# STM32H5F5 register map
File version: 1.0
CPU: CM33 r0p0, little endian, MPU, FPU, 4 interrupt priority bits
Registers are 32-bit, read-write, reset 0x0 unless marked. A register's access mark holds for its fields unless they carry their own. Offsets are from the block's base; [hi:lo] are bit positions; {n}, {i} and the like mark numbered series; 'fields as' and 'values as' point back to an identical list.

## RCC (part 1 of 2) — RCC register block
Base 0x44020C00
Same registers: RCC_S 0x54020C00
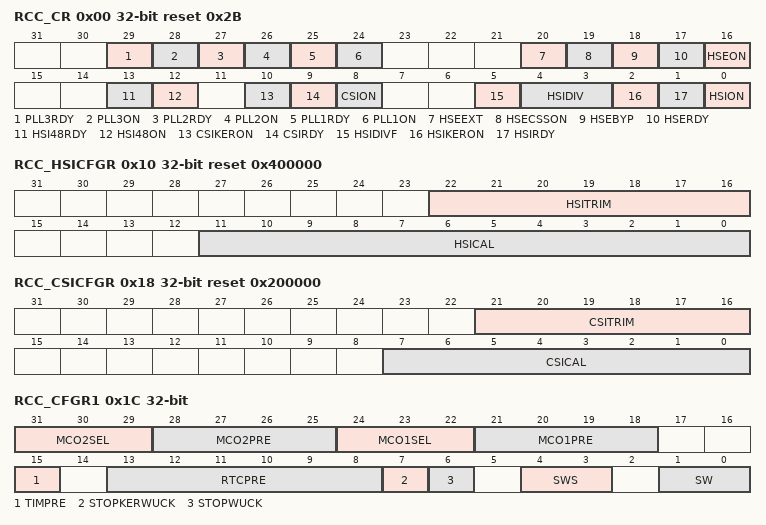
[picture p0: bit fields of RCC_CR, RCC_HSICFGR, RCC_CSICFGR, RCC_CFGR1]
0x00 RCC_CR reset 0x2B — RCC clock control register
  [29] PLL3RDY ro — PLL3 clock ready flag
    0=PLL3 unlocked (default after reset); 1=PLL3 locked
  [28] PLL3ON — PLL3 enable
    0=PLL3 OFF (default after reset); 1=PLL3 ON
  [27] PLL2RDY ro — PLL2 clock ready flag
    0=PLL2 unlocked; 1=PLL2 locked
  [26] PLL2ON — PLL2 enable
    0=PLL2 OFF (default after reset); 1=PLL2 ON
  [25] PLL1RDY ro — PLL1 clock ready flag
    0=PLL1 unlocked (default after reset); 1=PLL1 locked
  [24] PLL1ON — PLL1 enable
    0=PLL1 OFF (default after reset); 1=PLL1 ON
  [20] HSEEXT — external high speed clock type in Bypass mode
    0=HSE in analog mode (default after reset); 1=HSE in digital mode
  [19] HSECSSON — HSE clock security system enable
    0=CSS on HSE OFF (clock detector OFF) (default after reset); 1=CSS on HSE ON (clock detector ON if the HSE oscillator is stable, OFF if not)
  [18] HSEBYP — HSE clock bypass
    0=HSE oscillator not bypassed (default after reset); 1=HSE oscillator bypassed with an external clock
  [17] HSERDY ro — HSE clock ready flag
    0=HSE clock is not ready (default after reset); 1=HSE clock is ready
  [16] HSEON — HSE clock enable
    0=HSE is OFF (default after reset); 1=HSE is ON
  [13] HSI48RDY ro — HSI48 clock ready flag
    0=HSI48 clock is not ready (default after reset); 1=HSI48 clock is ready
  [12] HSI48ON — HSI48 clock enable
    0=HSI48 is OFF (default after reset); 1=HSI48 is ON
  [10] CSIKERON — CSI clock enable in Stop mode
    0=no effect on CSI (default after reset); 1=CSI is forced to ON even in Stop mode
  [9] CSIRDY ro — CSI clock ready flag
    0=CSI clock is not ready (default after reset); 1=CSI clock is ready
  [8] CSION — CSI clock enable
    0=CSI is OFF (default after reset); 1=CSI is ON
  [5] HSIDIVF ro — HSI divider flag
    0=new division ratio not yet propagated to hsi_ck, hsi_ker_ck (default after reset); 1=hsi_ck, hsi_ker_ck clock frequency reflects the new HSIDIV value (default register value when the clock setting is completed)
  [4:3] HSIDIV — HSI clock divider
    0=division by 1, hsi_ck, hsi_ker_ck = 64 MHz; 1=division by 2, hsi_ck, hsi_ker_ck = 32 MHz (default after reset); 2=division by 4, hsi_ck, hsi_ker_ck = 16 MHz; 3=division by 8, hsi_ck, hsi_ker_ck = 8 MHz
  [2] HSIKERON — HSI clock enable in Stop mode
    0=no effect on HSI (default after reset); 1=HSI is forced to ON even in Stop mode
  [1] HSIRDY ro — HSI clock ready flag
    0=HSI clock is not ready (default after reset); 1=HSI clock is ready
  [0] HSION — HSI clock enable
    0=HSI is OFF; 1=HSI is ON (default after reset)
0x10 RCC_HSICFGR reset 0x400000 (reset mask 0xFFFFF000) — RCC HSI calibration register
  [22:16] HSITRIM — HSI clock trimming
  [11:0] HSICAL ro — HSI clock calibration
0x14 RCC_CRRCR ro (reset mask 0xFFFFF000) — RCC clock recovery RC register
  [9:0] HSI48CAL — Internal RC 48 MHz clock calibration
0x18 RCC_CSICFGR reset 0x200000 (reset mask 0xFFFFF000) — RCC CSI calibration register
  [21:16] CSITRIM — CSI clock trimming
  [7:0] CSICAL — CSI clock calibration
0x1C RCC_CFGR1 — RCC clock configuration register1
  [31:29] MCO2SEL — microcontroller clock output 2
    0=system clock selected (sys_ck) (default after reset); 1=PLL2 oscillator clock selected (pll2_p_ck); 2=HSE clock selected (hse_ck); 3=PLL1 clock selected (pll1_p_ck); 4=CSI clock selected (csi_ck); 5=LSI clock selected (lsi_ck)
  [28:25] MCO2PRE — MCO2 prescaler
    0=prescaler disabled (default after reset); 1=division by 1 (bypass); 2=division by 2; 3=division by 3; 4=division by 4; 15=division by 15
  [24:22] MCO1SEL — Microcontroller clock output 1
    0=HSI clock selected (hsi_ck) (default after reset); 1=LSE oscillator clock selected (lse_ck); 2=HSE clock selected (hse_ck); 3=PLL1 clock selected (pll1_q_ck); 4=HSI48 clock selected (hsi48_ck)
  [21:18] MCO1PRE — MCO1 prescaler
    values as MCO2PRE
  [15] TIMPRE — timers clocks prescaler selection
    0=The timers kernel clock is equal to rcc_hclk1 if PPRE1 or PPRE2 corresponds to a division by 1 or 2, else it is equal to 2 x Fless thansub>rcc_pclk1less than/sub> or 2 x Fless thansub>rcc_pclk2less than/sub> (default after reset); 1=The timers kernel clock is equal to 2 x Fless thansub>rcc_pclk1less than/sub> or 2 x Fless thansub>rcc_pclk2less than/sub> if PPRE1 or PPRE2 corresponds to a division by 1, 2, or 4, else it is equal to 4 x Fless thansub>rcc_pclk1less than/sub> or 4 x Fless thansub>rcc_pclk2less than/sub>
  [13:8] RTCPRE — HSE division factor for RTC clock
    0=no clock (default after reset); 1=no clock; 2=HSE/2; 3=HSE/3; 4=HSE/4; 62=HSE/62; 63=HSE/63
  [7] STOPKERWUCK — kernel clock selection after a wake-up from system Stop
    0=HSI selected as wake-up clock from system Stop (default after reset); 1=CSI selected as wake-up clock from system Stop
  [6] STOPWUCK — system clock selection after a wake-up from system Stop
    1=CSI selected as wake-up clock from system Stop
  [4:3] SWS ro — system clock switch status
    0=HSI used as system clock (hsi_ck) (default after reset); 1=CSI used as system clock (csi_ck); 2=HSE used as system clock (hse_ck); 3=PLL1 used as system clock (pll1_p_ck)
  [1:0] SW — system clock and trace clock switch
    0=HSI selected as system clock (hsi_ck) (default after reset); 1=CSI selected as system clock (csi_ck); 2=HSE selected as system clock (hse_ck); 3=PLL1 selected as system clock (pll1_p_ck for sys_ck)
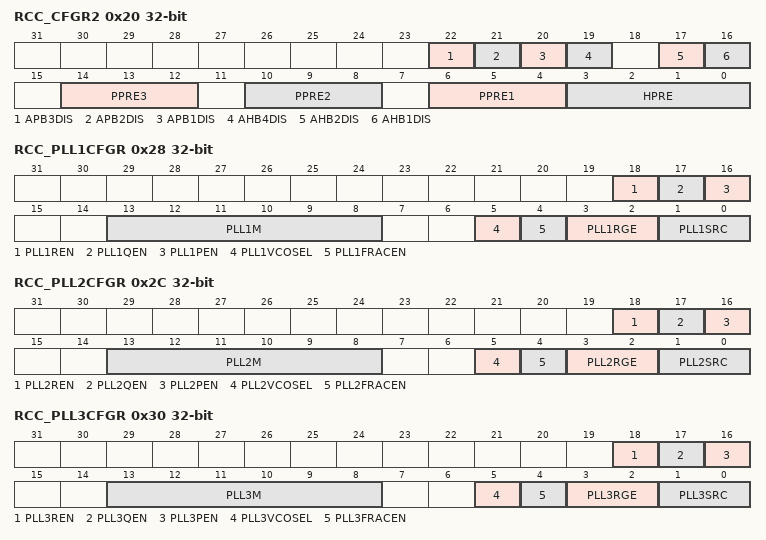
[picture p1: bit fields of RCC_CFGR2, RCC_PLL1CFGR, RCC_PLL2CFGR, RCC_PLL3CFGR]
0x20 RCC_CFGR2 — RCC CPU domain clock configuration register 2
  [22] APB3DIS — APB3 clock disable value.
    0=APB3 clock enabled, distributed to peripherals according to their dedicated clock enable control bits; 1=APB3 clock disabled
  [21] APB2DIS — APB2 clock disable value
    0=APB2 clock enabled, distributed to peripherals according to their dedicated clock enable control bits; 1=APB2 clock disabled
  [20] APB1DIS — APB1 clock disable value
    0=APB1 clock enabled, distributed to peripherals according to their dedicated clock enable control bits; 1=APB1 clock disabled
  [19] AHB4DIS — AHB4 clock disable
    0=AHB4 clock enabled, distributed to peripherals according to their dedicated clock enable control bits; 1=AHB4 clock disabled
  [17] AHB2DIS — AHB2 clock disable
    0=AHB2 clock enabled, distributed to peripherals according to their dedicated clock enable control bits; 1=AHB2 clock disabled
  [16] AHB1DIS — AHB1 clock disable
    0=AHB1 clock enabled, distributed to peripherals according to their dedicated clock enable control bits; 1=AHB1 clock disabled
  [14:12] PPRE3 — APB low-speed prescaler (APB3)
    4=rcc_pclk3 = rcc_hclk1 / 2; 5=rcc_pclk3 = rcc_hclk1 / 4; 6=rcc_pclk3 = rcc_hclk1 / 8; 7=rcc_pclk3 = rcc_hclk1 / 16
  [10:8] PPRE2 — APB high-speed prescaler (APB2)
    4=rcc_pclk2 = rcc_hclk1 / 2; 5=rcc_pclk2 = rcc_hclk1 / 4; 6=rcc_pclk2 = rcc_hclk1 / 8; 7=rcc_pclk2 = rcc_hclk1 / 16
  [6:4] PPRE1 — APB low-speed prescaler (APB1)
    4=rcc_pclk1 = rcc_hclk1 / 2; 5=rcc_pclk1 = rcc_hclk1 / 4; 6=rcc_pclk1 = rcc_hclk1 / 8; 7=rcc_pclk1 = rcc_hclk1 / 16
  [3:0] HPRE — AHB prescaler
    8=rcc_hclk = sys_ck / 2; 9=rcc_hclk = sys_ck / 4; 10=rcc_hclk = sys_ck / 8; 11=rcc_hclk = sys_ck / 16; 12=rcc_hclk = sys_ck / 64; 13=rcc_hclk = sys_ck / 128; 14=rcc_hclk = sys_ck / 256; 15=rcc_hclk = sys_ck / 512
0x28 RCC_PLL1CFGR — RCC PLL clock source selection register
  [18] PLL1REN — PLL1 DIVR divider output enable
    0=pll1_r_ck output disabled (default after reset); 1=pll1_r_ck output enabled
  [17] PLL1QEN — PLL1 DIVQ divider output enable
    0=pll1_q_ck output disabled (default after reset); 1=pll1_q_ck output enabled
  [16] PLL1PEN — PLL1 DIVP divider output enable
    0=pll1_p_ck output disabled (default after reset); 1=pll1_p_ck output enabled
  [13:8] PLL1M — prescaler for PLL1
    0=prescaler disabled (default after reset); 1=division by 1 (bypass); 2=division by 2; 3=division by 3; 32=division by 32; 63=division by 63
  [5] PLL1VCOSEL — PLL1 VCO selection
    0=wide VCO range: 192 to 836 MHz (default after reset); 1=medium VCO range: 150 to 420 MHz
  [4] PLL1FRACEN — PLL1 fractional latch enable
  [3:2] PLL1RGE — PLL1 input frequency range
    0=PLL1 input (ref1_ck) clock range frequency between 1 and 2 MHz (default after reset); 1=PLL1 input (ref1_ck) clock range frequency between 2 and 4 MHz; 2=PLL1 input (ref1_ck) clock range frequency between 4 and 8 MHz; 3=PLL1 input (ref1_ck) clock range frequency between 8 and 16 MHz
  [1:0] PLL1SRC — PLL1M and PLLs clock source selection
    0=no clock send to PLL1M divider and PLLs (default after reset); 1=HSI selected as PLL clock (hsi_ck); 2=CSI selected as PLL clock (csi_ck); 3=HSE selected as PLL clock (hse_ck)
0x2C RCC_PLL2CFGR — RCC PLL clock source selection register
  [18] PLL2REN — PLL2 DIVR divider output enable
    0=pll2_r_ck output disabled (default after reset); 1=pll2_r_ck output enabled
  [17] PLL2QEN — PLL2 DIVQ divider output enable
    0=pll2_q_ck output disabled (default after reset); 1=pll2_q_ck output enabled
  [16] PLL2PEN — PLL2 DIVP divider output enable
    0=pll2_p_ck output disabled (default after reset); 1=pll2_p_ck output enabled
  [13:8] PLL2M — prescaler for PLL2
    values as RCC_PLL1CFGR.PLL1M
  [5] PLL2VCOSEL — PLL2 VCO selection
    0=wide VCO range 192 to 836 MHz (default after reset); 1=medium VCO range 150 to 420 MHz
  [4] PLL2FRACEN — PLL2 fractional latch enable
    values as PLL2PEN
  [3:2] PLL2RGE — PLL2 input frequency range
    0=PLL2 input (ref2_ck) clock range frequency between 1 and 2 MHz (default after reset) 01: PLL2 input (ref2_ck) clock range frequency between 2 and 4 MHz; 2=PLL2 input (ref2_ck) clock range frequency between 4 and 8 MHz; 3=PLL2 input (ref2_ck) clock range frequency between 8 and 16 MHz
  [1:0] PLL2SRC — PLL2M and PLLs clock source selection
    0=no clock send to PLL2M divider and PLLs (default after reset); 1=HSI selected as PLL clock (hsi_ck); 2=CSI selected as PLL clock (csi_ck); 3=HSE selected as PLL clock (hse_ck)
0x30 RCC_PLL3CFGR — RCC PLL clock source selection register
  [18] PLL3REN — PLL3 DIVR divider output enable
    0=pll3_r_ck output disabled (default after reset); 1=pll3_r_ck output enabled
  [17] PLL3QEN — PLL3 DIVQ divider output enable
    0=pll3_q_ck output disabled (default after reset); 1=pll3_q_ck output enabled
  [16] PLL3PEN — PLL3 DIVP divider output enable
    0=pll3_p_ck output disabled (default after reset); 1=pll3_p_ck output enabled
  [13:8] PLL3M — prescaler for PLL3
    values as RCC_PLL1CFGR.PLL1M
  [5] PLL3VCOSEL — PLL3 VCO selection
    values as RCC_PLL2CFGR.PLL2VCOSEL
  [4] PLL3FRACEN — PLL3 fractional latch enable
  [3:2] PLL3RGE — PLL3 input frequency range
    0=PLL3 input (ref3_ck) clock range frequency between 1 and 2 MHz (default after reset); 1=PLL3 input (ref3_ck) clock range frequency between 2 and 4 MHz; 2=PLL3 input (ref3_ck) clock range frequency between 4 and 8 MHz; 3=PLL3 input (ref3_ck) clock range frequency between 8 and 16 MHz
  [1:0] PLL3SRC — PLL3M and PLLs clock source selection
    0=no clock send to PLL3M divider and PLLs (default after reset); 1=HSI selected as PLL clock (hsi_ck); 2=CSI selected as PLL clock (csi_ck); 3=HSE selected as PLL clock (hse_ck)
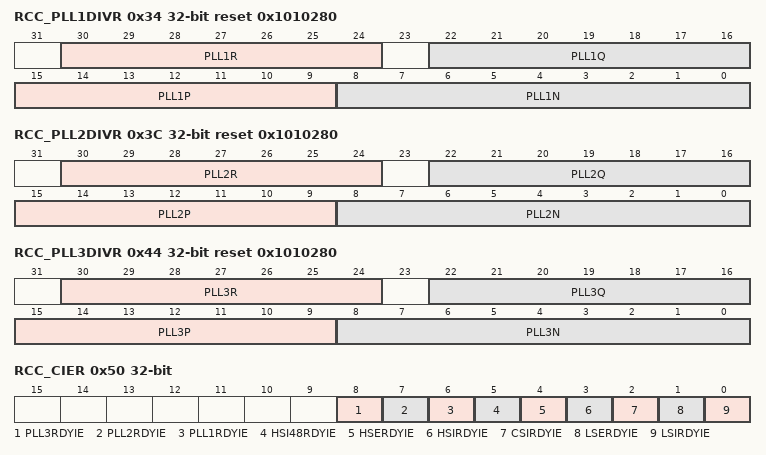
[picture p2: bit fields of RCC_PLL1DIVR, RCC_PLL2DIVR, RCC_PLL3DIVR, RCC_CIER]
0x34 RCC_PLL1DIVR reset 0x1010280 — RCC PLL1 dividers register
  [30:24] PLL1R — PLL1 DIVR division factor
    0=pll1_r_ck = vco1_ck / 1; 1=pll1_r_ck = vco1_ck / 2 (default after reset); 2=pll1_r_ck = vco1_ck / 3; 3=pll1_r_ck = vco1_ck / 4; 127=pll1_r_ck = vco1_ck / 128
  [22:16] PLL1Q — PLL1 DIVQ division factor
    0=pll1_q_ck = vco1_ck; 1=pll1_q_ck = vco1_ck / 2 (default after reset); 2=pll1_q_ck = vco1_ck / 3; 3=pll1_q_ck = vco1_ck / 4; 127=pll1_q_ck = vco1_ck / 128
  [15:9] PLL1P — PLL1 DIVP division factor
    0=Not allowed; 1=pll1_p_ck = vco1_ck / 2 (default after reset); 2=Not allowed; 3=pll1_p_ck = vco1_ck / 4; 127=pll1_p_ck = vco1_ck / 128
  [8:0] PLL1N — Multiplication factor for PLL1VCO
    3=PLL1N = 4; 4=PLL1N = 5; 5=PLL1N = 6; 128=PLL1N = 129 (default after reset); 0x1FF=PLL1N = 512
0x38 RCC_PLL1FRACR — RCC PLL1 fractional divider register
  [15:3] PLL1FRACN — fractional part of the multiplication factor for PLL1 VCO
0x3C RCC_PLL2DIVR reset 0x1010280 — RCC PLL1 dividers register
  [30:24] PLL2R — PLL2 DIVR division factor
    0=pll2_r_ck = vco2_ck; 1=pll2_r_ck = vco2_ck / 2 (default after reset); 2=pll2_r_ck = vco2_ck / 3; 3=pll2_r_ck = vco2_ck / 4; 127=pll2_r_ck = vco2_ck / 128
  [22:16] PLL2Q — PLL2 DIVQ division factor
    0=pll2_q_ck = vco2_ck; 1=pll2_q_ck = vco2_ck / 2 (default after reset); 2=pll2_q_ck = vco2_ck / 3; 3=pll2_q_ck = vco2_ck / 4; 127=pll2_q_ck = vco2_ck / 128
  [15:9] PLL2P — PLL2 DIVP division factor
    0=pll2_p_ck = vco2_ck; 1=pll2_p_ck = vco2_ck / 2 (default after reset); 2=pll2_p_ck = vco2_ck / 3; 3=pll2_p_ck = vco2_ck / 4; 127=pll2_p_ck = vco2_ck / 128
  [8:0] PLL2N — Multiplication factor for PLL2VCO
    3=PLL2N = 4; 4=PLL2N = 5; 5=PLL2N = 6; 128=PLL2N = 129 (default after reset); 0x1FF=PLL2N = 512
0x40 RCC_PLL2FRACR — RCC PLL2 fractional divider register
  [15:3] PLL2FRACN — fractional part of the multiplication factor for PLL2 VCO
0x44 RCC_PLL3DIVR reset 0x1010280 — RCC PLL3 dividers register
  [30:24] PLL3R — PLL3 DIVR division factor
    0=pll3_r_ck = vco3_ck; 1=pll3_r_ck = vco3_ck / 2 (default after reset); 2=pll3_r_ck = vco3_ck / 3; 3=pll3_r_ck = vco3_ck / 4; 127=pll3_r_ck = vco3_ck / 128
  [22:16] PLL3Q — PLL3 DIVQ division factor
    0=pll3_q_ck = vco3_ck; 1=pll3_q_ck = vco3_ck / 2 (default after reset); 2=pll3_q_ck = vco3_ck / 3; 3=pll3_q_ck = vco3_ck / 4; 127=pll3_q_ck = vco3_ck / 128
  [15:9] PLL3P — PLL3 DIVP division factor
    0=pll3_p_ck = vco3_ck; 1=pll3_p_ck = vco3_ck / 2 (default after reset); 2=pll3_p_ck = vco3_ck / 3; 3=pll3_p_ck = vco3_ck / 4; 127=pll3_p_ck = vco3_ck / 128
  [8:0] PLL3N — Multiplication factor for PLL3VCO
    3=PLL3N = 4; 4=PLL3N = 5; 5=PLL3N = 6; 128=PLL3N = 129 (default after reset); 0x1FF=PLL3N = 512
0x48 RCC_PLL3FRACR — RCC PLL3 fractional divider register
  [15:3] PLL3FRACN — Fractional part of the multiplication factor for PLL3 VCO
0x50 RCC_CIER — RCC clock source interrupt enable register
  [8] PLL3RDYIE — PLL3 ready interrupt enable
    0=PLL3 lock interrupt disabled (default after reset); 1=PLL3 lock interrupt enabled
  [7] PLL2RDYIE — PLL2 ready interrupt enable
    0=PLL2 lock interrupt disabled (default after reset); 1=PLL2 lock interrupt enabled
  [6] PLL1RDYIE — PLL1 ready interrupt enable
    0=PLL1 lock interrupt disabled (default after reset); 1=PLL1 lock interrupt enabled
  [5] HSI48RDYIE — HSI48 ready interrupt enable
    0=HSI48 ready interrupt disabled (default after reset); 1=HSI48 ready interrupt enabled
  [4] HSERDYIE — HSE ready interrupt enable
    0=HSE ready interrupt disabled (default after reset); 1=HSE ready interrupt enabled
  [3] HSIRDYIE — HSI ready interrupt enable
    0=HSI ready interrupt disabled (default after reset); 1=HSI ready interrupt enabled
  [2] CSIRDYIE — CSI ready interrupt enable
    0=CSI ready interrupt disabled (default after reset); 1=CSI ready interrupt enabled
  [1] LSERDYIE — LSE ready interrupt enable
    0=LSE ready interrupt disabled (default after reset); 1=LSE ready interrupt enabled
  [0] LSIRDYIE — LSI ready interrupt enable
    0=LSI ready interrupt disabled (default after reset); 1=LSI ready interrupt enabled
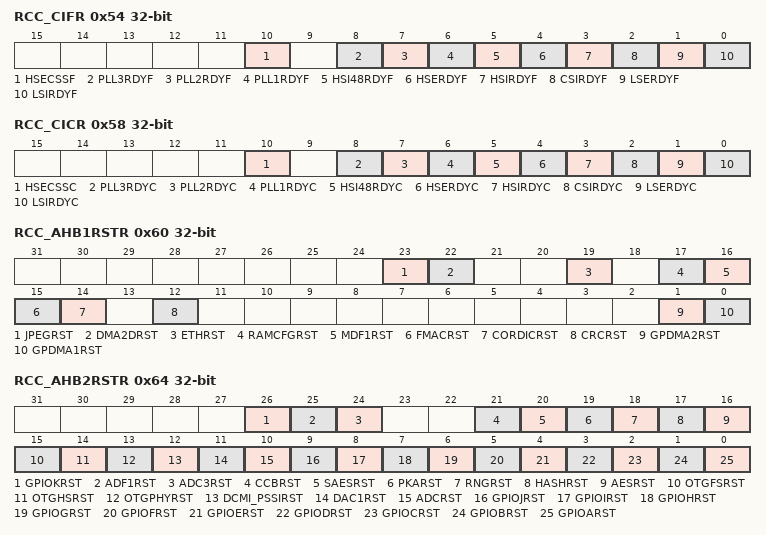
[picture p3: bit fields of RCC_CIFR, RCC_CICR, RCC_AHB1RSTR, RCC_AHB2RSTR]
0x54 RCC_CIFR ro — RCC clock source interrupt flag register
  [10] HSECSSF — HSE clock security system interrupt flag
    0=no clock security interrupt caused by HSE clock failure (default after reset); 1=clock security interrupt caused by HSE clock failure
  [8] PLL3RDYF — PLL3 ready interrupt flag
    0=no clock ready interrupt caused by PLL3 lock (default after reset); 1=clock ready interrupt caused by PLL3 lock
  [7] PLL2RDYF — PLL2 ready interrupt flag
    0=no clock ready interrupt caused by PLL2 lock (default after reset); 1=clock ready interrupt caused by PLL2 lock
  [6] PLL1RDYF — PLL1 ready interrupt flag
    0=no clock ready interrupt caused by PLL1 lock (default after reset); 1=clock ready interrupt caused by PLL1 lock
  [5] HSI48RDYF — HSI48 ready interrupt flag
    0=no clock ready interrupt caused by the HSI48 oscillator (default after reset); 1=clock ready interrupt caused by the HSI48 oscillator
  [4] HSERDYF — HSE ready interrupt flag
    0=no clock ready interrupt caused by the HSE (default after reset); 1=clock ready interrupt caused by the HSE
  [3] HSIRDYF — HSI ready interrupt flag
    0=no clock ready interrupt caused by the HSI (default after reset); 1=clock ready interrupt caused by the HSI
  [2] CSIRDYF — CSI ready interrupt flag
    0=no clock ready interrupt caused by the CSI (default after reset); 1=clock ready interrupt caused by the CSI
  [1] LSERDYF — LSE ready interrupt flag
    0=no clock ready interrupt caused by the LSE (default after reset); 1=clock ready interrupt caused by the LSE
  [0] LSIRDYF — LSI ready interrupt flag
    0=no clock ready interrupt caused by the LSI (default after reset); 1=clock ready interrupt caused by the LSI
0x58 RCC_CICR — RCC clock source interrupt clear register
  [10] HSECSSC — HSE clock security system interrupt clear
    0=HSECSSF no effect (default after reset); 1=HSECSSF cleared
  [8] PLL3RDYC — PLL3 ready interrupt clear
    0=PLL3RDYF no effect (default after reset); 1=PLL3RDYF cleared
  [7] PLL2RDYC — PLL2 ready interrupt clear
    0=PLL2RDYF no effect (default after reset); 1=PLL2RDYF cleared
  [6] PLL1RDYC — PLL1 ready interrupt clear
    0=PLL1RDYF no effect (default after reset); 1=PLL1RDYF cleared
  [5] HSI48RDYC — HSI48 ready interrupt clear
    0=HSI48RDYF no effect (default after reset); 1=HSI48RDYF cleared
  [4] HSERDYC — HSE ready interrupt clear
    0=HSERDYF no effect (default after reset); 1=HSERDYF cleared
  [3] HSIRDYC — HSI ready interrupt clear
    0=HSIRDYF no effect (default after reset); 1=HSIRDYF cleared
  [2] CSIRDYC — HSI ready interrupt clear
    0=CSIRDYF no effect (default after reset); 1=CSIRDYF cleared
  [1] LSERDYC — LSE ready interrupt clear
    0=LSERDYF no effect (default after reset); 1=LSERDYF cleared
  [0] LSIRDYC — LSI ready interrupt clear
    0=LSIRDYF no effect (default after reset); 1=LSIRDYF cleared
0x60 RCC_AHB1RSTR — RCC AHB1 reset register
  [23] JPEGRST — JPEG reset
    0=does not reset JPEG (default after reset); 1=resets the JPEG
  [22] DMA2DRST — DMA2D reset
    0=does not reset DMA2D (default after reset); 1=resets the DMA2D
  [19] ETHRST — ETHRST reset
    0=does not reset ETHRST (default after reset); 1=resets the ETHRST
  [17] RAMCFGRST — RAMCFG reset
    0=does not reset RAMCFG (default after reset); 1=resets RAMCFG
  [16] MDF1RST — MDF1 reset
    0=does not reset MDF1 (default after reset); 1=resets MDF1
  [15] FMACRST — FMAC reset
    0=does not reset FMAC (default after reset); 1=resets FMAC
  [14] CORDICRST — CORDIC reset
    0=does not reset CORDIC (default after reset); 1=resets CORDIC
  [12] CRCRST — CRC reset
    0=does not reset CRC (default after reset); 1=resets CRC
  [1] GPDMA2RST — GPDMA2 reset
    0=does not reset GPDMA2 (default after reset); 1=resets GPDMA2
  [0] GPDMA1RST — GPDMA1 reset
    0=does not reset GPDMA1 (default after reset); 1=resets GPDMA1
0x64 RCC_AHB2RSTR — RCC AHB2 peripheral reset register
  [26] GPIOKRST — GPIOK reset
    0=does not reset the GPIOK (default after reset); 1=resets the GPIOK
  [25] ADF1RST — ADF1 reset
    0=does not reset ADF1 (default after reset); 1=resets ADF1
  [24] ADC3RST — ADC3 reset
    0=does not reset ADC3 (default after reset); 1=resets ADC3
  [21] CCBRST — CCB reset
    0=does not reset CCB (default after reset); 1=resets CCB
  [20] SAESRST — SAES reset
    0=does not reset SAES (default after reset); 1=resets SAES
  [19] PKARST — PKA block reset
    0=does not reset PKA (default after reset); 1=resets PKA
  [18] RNGRST — RNG reset
    0=does not reset RNG (default after reset); 1=resets RNG
  [17] HASHRST — HASH reset
    0=does not reset HASH (default after reset); 1=resets HASH
  [16] AESRST — AES reset
    0=does not reset AES (default after reset); 1=resets AES
  [15] OTGFSRST — OTGFS reset
    0=does not reset OTGFS (default after reset); 1=resets OTGFS
  [14] OTGHSRST — OTGHS reset
    0=does not reset OTGHS (default after reset); 1=resets OTGHS
  [13] OTGPHYRST — OTGPHY reset
    0=does not reset the OTGPHY (default after reset); 1=resets the OTGPHY
  [12] DCMI_PSSIRST — Digital camera interface reset (DCMI or PSSI depending which one is active)
    0=does not reset the DCMI/PSSI (default after reset); 1=resets the DCMI/PSSI
  [11] DAC1RST — DAC1 reset
    0=does not reset DAC1 (default after reset); 1=resets DAC1
  [10] ADCRST — ADC1 and ADC2 reset
    0=does not reset ADC1 and ADC2 (default after reset); 1=resets ADC1 and ADC2
  [9] GPIOJRST — GPIOJ reset
    0=does not reset the GPIOJ (default after reset); 1=resets the GPIOJ
  [8] GPIOIRST — GPIOI reset
    0=does not reset the GPIOI (default after reset); 1=resets the GPIOI
  [7] GPIOHRST — GPIOH reset
    0=does not reset the GPIOH (default after reset); 1=resets the GPIOH
  [6] GPIOGRST — GPIOG reset
    0=does not reset the GPIOG (default after reset); 1=resets the GPIOG
  [5] GPIOFRST — GPIOF reset
    0=does not reset the GPIOF (default after reset); 1=resets the GPIOF
  [4] GPIOERST — GPIOE reset
    0=does not reset the GPIOE (default after reset); 1=resets the GPIOE
  [3] GPIODRST — GPIOD reset
    0=does not reset the GPIOD (default after reset); 1=resets the GPIOD
  [2] GPIOCRST — GPIOC reset
    0=does not reset the GPIOC (default after reset); 1=resets the GPIOC
  [1] GPIOBRST — GPIOB reset
    0=does not reset the GPIOB (default after reset); 1=resets the GPIOB
  [0] GPIOARST — GPIOA reset
    0=does not reset the GPIOA (default after reset); 1=resets the GPIOA
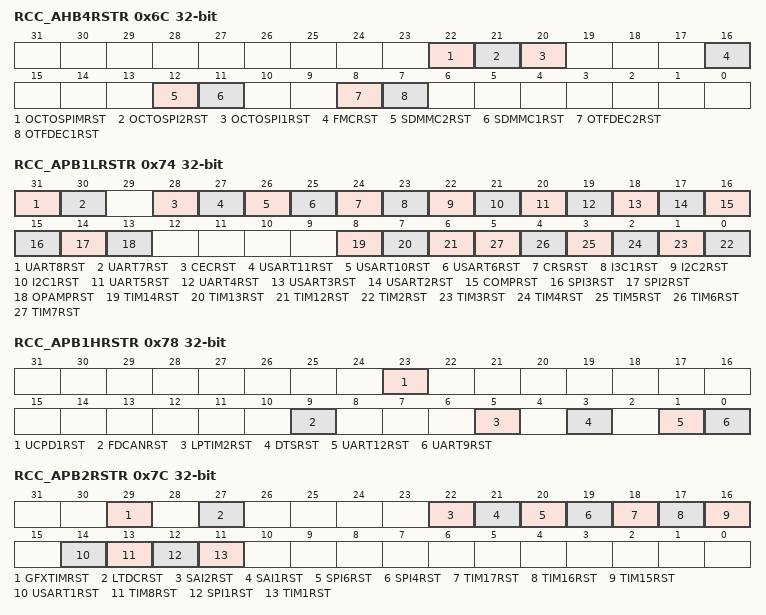
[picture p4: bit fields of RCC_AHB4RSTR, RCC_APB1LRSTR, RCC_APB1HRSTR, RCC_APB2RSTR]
0x6C RCC_AHB4RSTR — RCC AHB4 peripheral reset register
  [22] OCTOSPIMRST — OCTOSPIM reset
    0=does not reset OCTOSPIM (default after reset); 1=resets OCTOSPIM
  [21] OCTOSPI2RST — OCTOSPI2 reset
    0=does not reset OCTOSPI2 (default after reset); 1=resets OCTOSPI2
  [20] OCTOSPI1RST — OCTOSPI1 reset
    0=does not reset OCTOSPI1 (default after reset); 1=resets OCTOSPI1
  [16] FMCRST — FMC reset
    0=does not reset FMC (default after reset); 1=resets FMC
  [12] SDMMC2RST — SDMMC2 and SDMMC2 delay reset
    0=does not reset SDMMC2 and SDMMC2 delay (default after reset); 1=resets SDMMC2 and SDMMC2 delay
  [11] SDMMC1RST — SDMMC1 and SDMMC1 delay reset
    0=does not reset SDMMC1 and SDMMC1 delay (default after reset); 1=resets SDMMC1 and SDMMC1 delay
  [8] OTFDEC2RST — OTFDEC2 reset
    0=does not reset OTFDEC2 (default after reset); 1=resets OTFDEC2
  [7] OTFDEC1RST — OTFDEC1 reset
    0=does not reset OTFDEC1 (default after reset); 1=resets OTFDEC1
0x74 RCC_APB1LRSTR — RCC APB1 peripheral low reset register
  [31] UART8RST — UART8 reset
    0=does not reset the UART8 (default after reset); 1=resets the UART8
  [30] UART7RST — UART7 reset
    0=does not reset the UART7 (default after reset); 1=resets the UART7
  [28] CECRST — HDMI-CEC reset
    0=does not reset the HDMI-CEC (default after reset); 1=resets the HDMI-CEC
  [27] USART11RST — USART11 reset
    0=does not reset the USART11 (default after reset); 1=resets the USART11
  [26] USART10RST — USART10 reset
    0=does not reset the USART10 (default after reset); 1=resets the USART10
  [25] USART6RST — USART6 reset
    0=does not reset the USART6 (default after reset); 1=resets the USART6
  [24] CRSRST — CRS reset
    0=does not reset the CRS (default after reset); 1=resets the CRS
  [23] I3C1RST — I3C1 reset
    0=does not reset the I3C1 (default after reset); 1=resets the I3C1
  [22] I2C2RST — I2C2 block reset
    0=does not reset the I2C2 block (default after reset); 1=resets the I2C2 block
  [21] I2C1RST — I2C1 reset
    0=does not reset the I2C1 (default after reset); 1=resets the I2C1
  [20] UART5RST — UART5 reset
    0=does not reset the UART5 (default after reset); 1=resets the UART5
  [19] UART4RST — UART4 reset
    0=does not reset the UART4 (default after reset); 1=resets the UART4
  [18] USART3RST — USART3 reset
    0=does not reset the USART3 (default after reset); 1=resets the USART3
  [17] USART2RST — USART2 reset
    0=does not reset the USART2 (default after reset); 1=resets the USART2
  [16] COMPRST — COMP reset
    0=does not reset the COMP (default after reset); 1=resets the COMP
  [15] SPI3RST — SPI3 reset
    0=does not reset the SPI3 (default after reset); 1=resets the SPI3
  [14] SPI2RST — SPI2 reset
    0=does not reset the SPI2 (default after reset); 1=resets the SPI2
  [13] OPAMPRST — OPAMP reset
    0=does not reset the OPAMP (default after reset); 1=resets the OPAMP
  [8] TIM14RST — TIM14 reset
    0=does not reset the TIM14 (default after reset); 1=resets the TIM14
  [7] TIM13RST — TIM13 reset
    0=does not reset the TIM13 (default after reset); 1=resets the TIM13
  [6] TIM12RST — TIM12 reset
    0=does not reset the TIM12 (default after reset); 1=resets the TIM12
  [n-2] TIM{n}RST (n=2..7) — TIM{n} reset
    0=does not reset the TIM{n} (default after reset); 1=resets the TIM{n}
0x78 RCC_APB1HRSTR — RCC APB1 peripheral high reset register
  [23] UCPD1RST — UCPD1 reset
    0=does not reset the UCPD1 (default after reset); 1=resets the UCPD1
  [9] FDCANRST — FDCAN1/2 reset
    0=does not reset the FDCAN1/2 (default after reset); 1=resets the FDCAN1/2
  [5] LPTIM2RST — LPTIM2 reset
    0=does not reset the LPTIM2 (default after reset); 1=resets the LPTIM2
  [3] DTSRST — DTS reset
    0=does not reset the DTS (default after reset); 1=resets the DTS
  [1] UART12RST — UART12 reset
    0=does not reset the UART12 (default after reset); 1=resets the UART12
  [0] UART9RST — UART9 reset
    0=does not reset UART9 (default after reset); 1=resets UART9
0x7C RCC_APB2RSTR — RCC APB2 peripheral reset register
  [29] GFXTIMRST — GFXTIM reset
    0=does not reset the GFXTIM (default after reset); 1=resets the GFXTIM
  [27] LTDCRST — LTDC reset
    0=does not reset the LTDC (default after reset); 1=resets the LTDC
  [22] SAI2RST — SAI2 reset
    0=does not reset the SAI2 (default after reset); 1=resets the SAI2
  [21] SAI1RST — SAI1 reset
    0=does not reset the SAI1 (default after reset); 1=resets the SAI1
  [20] SPI6RST — SPI6 reset
    0=does not reset the SPI6 (default after reset); 1=resets the SPI6
  [19] SPI4RST — SPI4 reset
    0=does not reset the SPI4 (default after reset); 1=resets the SPI4
  [18] TIM17RST — TIM17 reset
    0=does not reset the TIM17 (default after reset); 1=resets the TIM17
  [17] TIM16RST — TIM16 reset
    0=does not reset the TIM16 (default after reset); 1=resets the TIM16
  [16] TIM15RST — TIM15 reset
    0=does not reset the TIM15 (default after reset); 1=resets the TIM15
  [14] USART1RST — USART1 reset
    0=does not reset the USART1 (default after reset); 1=resets the USART1
  [13] TIM8RST — TIM8 reset
    0=does not reset the TIM8 (default after reset); 1=resets the TIM8
  [12] SPI1RST — SPI1 reset
    0=does not reset the SPI1 (default after reset); 1=resets the SPI1
  [11] TIM1RST — TIM1 reset
    0=does not reset the TIM1 (default after reset); 1=resets the TIM1
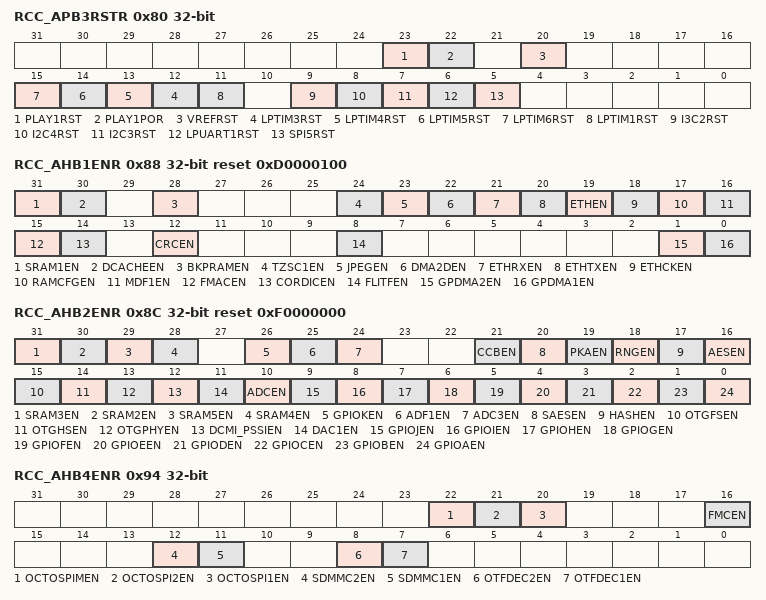
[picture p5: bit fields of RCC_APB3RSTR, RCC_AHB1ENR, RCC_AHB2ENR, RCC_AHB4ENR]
0x80 RCC_APB3RSTR — RCC APB3 peripheral reset register
  [23] PLAY1RST — PLAY1 reset
    0=does not reset the PLAY1 (default after reset); 1=resets the PLAY1
  [22] PLAY1POR — PLAY1 POR reset
    values as PLAY1RST
  [20] VREFRST — VREFBUF reset
    0=does not reset the VREFBUF (default after reset); 1=resets the VREFBUF
  [n+9] LPTIM{n}RST (n=3..6) — LPTIM{n} reset
    0=does not reset the LPTIM{n} (default after reset); 1=resets the LPTIM{n}
  [11] LPTIM1RST — LPTIM1 reset
    0=does not reset the LPTIM1 (default after reset); 1=resets the LPTIM1
  [9] I3C2RST — I3C2 reset
    0=does not reset the I3C2 (default after reset); 1=resets the I3C2
  [8] I2C4RST — I2C4 reset
    0=does not reset the I2C4 (default after reset); 1=resets the I2C4
  [7] I2C3RST — I2C3 reset
    0=does not reset the I2C3 (default after reset); 1=resets the I2C3
  [6] LPUART1RST — LPUART1 reset
    0=does not reset the LPUART1 (default after reset); 1=resets the LPUART1
  [5] SPI5RST — SPI5 reset
    0=does not reset the SPI5 (default after reset); 1=resets the SPI5
0x88 RCC_AHB1ENR reset 0xD0000100 — RCC AHB1 peripheral clock register
  [31] SRAM1EN — SRAM1 clock enable
    0=SRAM1 clock disabled; 1=SRAM1 clock enabled (default after reset)
  [30] DCACHEEN — DCACHE clock enable
    0=DCACHE clock disabled (default after reset); 1=DCACHE clock enabled
  [28] BKPRAMEN — BKPRAM clock enable
    0=BKPRAM clock disabled (default after reset); 1=BKPRAM clock enabled
  [24] TZSC1EN — TZSC1 clock enable
    0=TZSC1 clock disabled (default after reset); 1=TZSC1 clock enabled
  [23] JPEGEN — JPEG clock enable
    0=JPEG clock disabled (default after reset); 1=JPEG clock enabled
  [22] DMA2DEN — DMA2D clock enable
    0=DMA2D clock disabled (default after reset); 1=DMA2D clock enabled
  [21] ETHRXEN — ETHRX clock enable
    0=ETHRX clock disabled (default after reset); 1=ETHRX clock enabled
  [20] ETHTXEN — ETHTX clock enable
    0=ETHTX clock disabled (default after reset); 1=ETHTX clock enabled
  [19] ETHEN — ETH clock enable
    0=ETH clock disabled (default after reset); 1=ETH clock enabled
  [18] ETHCKEN — ETH internal clock enable
    0=ETH internal clock disabled (default after reset); 1=ETH internal clock enabled
  [17] RAMCFGEN — RAMCFG clock enable
    0=RAMCFG clock disabled (default after reset); 1=RAMCFG clock enabled
  [16] MDF1EN — MDF1 clock enable
    0=MDF1 clock disabled (default after reset); 1=MDF1 clock enabled
  [15] FMACEN — FMAC clock enable
    0=FMAC clock disabled (default after reset); 1=FMAC clock enabled
  [14] CORDICEN — CORDIC clock enable
    0=CORDIC clock disabled (default after reset); 1=CORDIC clock enabled
  [12] CRCEN — CRC clock enable
    0=CRC clock disabled (default after reset); 1=CRC clock enabled
  [8] FLITFEN — Flash interface clock enable
    0=FLASH clock disabled; 1=FLASH clock enabled (default after reset)
  [1] GPDMA2EN — GPDMA2 clock enable
    0=GPDMA2 clock disabled (default after reset); 1=GPDMA2 clock enabled
  [0] GPDMA1EN — GPDMA1 clock enable
    0=GPDMA1 clock disabled (default after reset); 1=GPDMA1 clock enabled
0x8C RCC_AHB2ENR reset 0xF0000000 — RCC AHB2 peripheral clock register
  [31] SRAM3EN — SRAM3 clock enable
    0=SRAM3 clock disabled; 1=SRAM3 clock enabled (default after reset)
  [30] SRAM2EN — SRAM2 clock enable
    0=SRAM2 clock disabled; 1=SRAM2 clock enabled (default after reset)
  [29] SRAM5EN — SRAM5 clock enable
    0=SRAM5 clock disabled; 1=SRAM5 clock enabled (default after reset)
  [28] SRAM4EN — SRAM4 clock enable
    0=SRAM4 clock disabled; 1=SRAM4 clock enabled (default after reset)
  [26] GPIOKEN — GPIOK clock enable
    0=GPIOK clock disabled (default after reset); 1=GPIOK clock enabled
  [25] ADF1EN — ADF1 clock enable
    0=ADF1 clock disabled; 1=ADF1 clock enabled (default after reset)
  [24] ADC3EN — ADC3 clock enable
    0=ADC3 clock disabled; 1=ADC3 clock enabled (default after reset)
  [21] CCBEN — CCB clock enable
    0=CCB clock disabled (default after reset); 1=CCB clock enabled
  [20] SAESEN — SAES clock enable
    0=SAES clock disabled (default after reset); 1=SAES clock enabled
  [19] PKAEN — PKA clock enable
    0=PKA clock disabled (default after reset); 1=PKA clock enabled
  [18] RNGEN — RNG clock enable
    0=RNG clock disabled (default after reset); 1=RNG clock enabled
  [17] HASHEN — HASH clock enable
    0=HASH clock disabled (default after reset); 1=HASH clock enabled
  [16] AESEN — AES clock enable
    0=AES clock disabled (default after reset); 1=AES clock enabled
  [15] OTGFSEN — OTGFS clock enable
    0=OTGFS clock disabled (default after reset); 1=OTGFS clock enabled
  [14] OTGHSEN — OTGHS clock enable
    0=OTGHS clock disabled (default after reset); 1=OTGHS clock enabled
  [13] OTGPHYEN — OTGPHY clock enable
    0=OTGPHY clock disabled (default after reset); 1=OTGPHY clock enabled
  [12] DCMI_PSSIEN — digital camera interface clock enable (DCMI or PSSI, depending which interface is active)
    0=DCMI/PSSI clock disabled (default after reset); 1=DCMI/PSSI clock enabled
  [11] DAC1EN — DAC clock enable
    0=DAC clock disabled (default after reset); 1=DAC clock enabled
  [10] ADCEN — ADC1 and 2 peripherals clock enable
    0=ADC1 and 2 clock disabled (default after reset); 1=ADC1 and 2 clock enabled
  [9] GPIOJEN — GPIOJ clock enable
    0=GPIOJ clock disabled (default after reset); 1=GPIOJ clock enabled
  [8] GPIOIEN — GPIOI clock enable
    0=GPIOI clock disabled (default after reset); 1=GPIOI clock enabled
  [7] GPIOHEN — GPIOH clock enable
    0=GPIOH clock disabled (default after reset); 1=GPIOH clock enabled
  [6] GPIOGEN — GPIOG clock enable
    0=GPIOG clock disabled (default after reset); 1=GPIOG clock enabled
  [5] GPIOFEN — GPIOF clock enable
    0=GPIOF clock disabled (default after reset); 1=GPIOF clock enabled
  [4] GPIOEEN — GPIOE clock enable
    0=GPIOE clock disabled (default after reset); 1=GPIOE clock enabled
  [3] GPIODEN — GPIOD clock enable
    0=GPIOD clock disabled (default after reset); 1=GPIOD clock enabled
  [2] GPIOCEN — GPIOC clock enable
    0=GPIOC clock disabled (default after reset); 1=GPIOC clock enabled
  [1] GPIOBEN — GPIOB clock enable
    0=GPIOB clock disabled (default after reset); 1=GPIOB clock enabled
  [0] GPIOAEN — GPIOA clock enable
    0=GPIOA clock disabled (default after reset); 1=GPIOA clock enabled
0x94 RCC_AHB4ENR — RCC AHB4 peripheral clock register
  [22] OCTOSPIMEN — OCTOSPIM clock enable
    0=OCTOSPIM clock disabled (default after reset); 1=OCTOSPIM clock enabled
  [21] OCTOSPI2EN — OCTOSPI2 clock enable
    0=OCTOSPI2 clock disabled (default after reset); 1=OCTOSPI2 clock enabled
  [20] OCTOSPI1EN — OCTOSPI1 clock enable
    0=OCTOSPI1 clock disabled (default after reset); 1=OCTOSPI1 clock enabled
  [16] FMCEN — FMC clock enable
    0=FMC clock disabled (default after reset); 1=FMC clock enabled
  [12] SDMMC2EN — SDMMC2 and SDMMC2 delay peripheral clock enable
    0=SDMMC2 and SDMMC2 delay clock disabled (default after reset); 1=SDMMC2 and SDMMC2 delay clock enabled
  [11] SDMMC1EN — SDMMC1 and SDMMC1 delay peripheral clock enable reset
    0=SDMMC1 and SDMMC1 delay clock disabled (default after reset); 1=SDMMC1 and SDMMC1 delay clock enabled
  [8] OTFDEC2EN — OTFDEC2 clock enable
    0=OTFDEC2 clock disabled (default after reset); 1=OTFDEC2 clock enabled
  [7] OTFDEC1EN — OTFDEC1 clock enable
    0=OTFDEC1 clock disabled (default after reset); 1=OTFDEC1 clock enabled
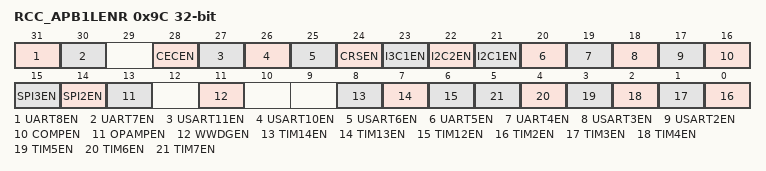
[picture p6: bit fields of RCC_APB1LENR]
0x9C RCC_APB1LENR — RCC APB1 peripheral clock register
  [31] UART8EN — UART8 clock enable
    0=UART8 clock disabled (default after reset); 1=UART8 clock enabled
  [30] UART7EN — UART7 clock enable
    0=UART7 clock disabled (default after reset); 1=UART7 clock enabled
  [28] CECEN — HDMI-CEC clock enable
    0=HDMI-CEC clock disabled (default after reset); 1=HDMI-CEC clock enabled
  [27] USART11EN — USART11 clock enable
    0=USART11 clock disabled (default after reset); 1=USART11 clock enabled
  [26] USART10EN — USART10 clock enable
    0=USART10 clock disabled (default after reset); 1=USART10 clock enabled
  [25] USART6EN — USART6 clock enable
    0=USART6 clock disabled (default after reset); 1=USART6 clock enabled
  [24] CRSEN — CRS clock enable
    0=CRS clock disabled (default after reset); 1=CRS clock enabled
  [23] I3C1EN — I3C1 clock enable
    0=I3C1 clock disabled (default after reset); 1=I3C1 clock enabled
  [22] I2C2EN — I2C2 clock enable
    0=I2C2 clock disabled (default after reset); 1=I2C2 clock enabled
  [21] I2C1EN — I2C1 clock enable
    0=I2C1 clock disabled (default after reset); 1=I2C1 clock enabled
  [20] UART5EN — UART5 clock enable
    0=UART5 clock disabled (default after reset); 1=UART5 clock enabled
  [19] UART4EN — UART4 clock enable
    0=UART4 clock disabled (default after reset); 1=UART4 clock enabled
  [18] USART3EN — USART3 clock enable
    0=USART3 clock disabled (default after reset); 1=USART3 clock enabled
  [17] USART2EN — USART2 clock enable
    0=USART2 clock disabled (default after reset); 1=USART2 clock enabled
  [16] COMPEN — COMP clock enable
    0=COMP clock disabled (default after reset); 1=COMP clock enabled
  [15] SPI3EN — SPI3 clock enable
    0=SPI3 clock disabled (default after reset); 1=SPI3 clock enabled
  [14] SPI2EN — SPI2 clock enable
    0=SPI2 clock disabled (default after reset); 1=SPI2 clock enabled
  [13] OPAMPEN — OPAMP clock enable
    0=OPAMP clock disabled (default after reset); 1=OPAMP clock enabled
  [11] WWDGEN — WWDG clock enable
    0=WWDG clock disabled (default after reset); 1=WWDG clock enabled
  [8] TIM14EN — TIM14 clock enable
    0=TIM14 clock disabled (default after reset); 1=TIM14 clock enabled
  [7] TIM13EN — TIM13 clock enable
    0=TIM13 clock disabled (default after reset); 1=TIM13 clock enabled
  [6] TIM12EN — TIM12 clock enable
    0=TIM12 clock disabled (default after reset); 1=TIM12 clock enabled
  [n-2] TIM{n}EN (n=2..7) — TIM{n} clock enable
    0=TIM{n} clock disabled (default after reset); 1=TIM{n} clock enabled
